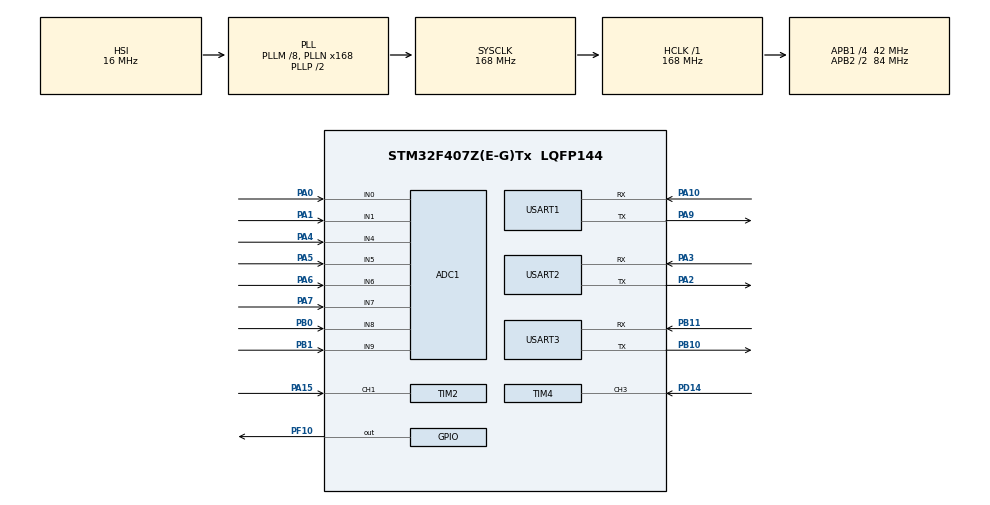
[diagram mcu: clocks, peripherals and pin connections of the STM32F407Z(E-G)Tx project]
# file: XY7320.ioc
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ADC1.Channel-0\#ChannelRegularConversion=ADC_CHANNEL_0
ADC1.Channel-1\#ChannelRegularConversion=ADC_CHANNEL_1
ADC1.Channel-2\#ChannelRegularConversion=ADC_CHANNEL_4
ADC1.Channel-3\#ChannelRegularConversion=ADC_CHANNEL_5
ADC1.Channel-4\#ChannelRegularConversion=ADC_CHANNEL_6
ADC1.Channel-5\#ChannelRegularConversion=ADC_CHANNEL_7
ADC1.Channel-6\#ChannelRegularConversion=ADC_CHANNEL_8
ADC1.Channel-7\#ChannelRegularConversion=ADC_CHANNEL_9
ADC1.DMAContinuousRequests=ENABLE
ADC1.ExternalTrigConv=ADC_EXTERNALTRIGCONV_T3_TRGO
ADC1.NbrOfConversion=8
ADC1.NbrOfConversionFlag=1
ADC1.Rank-0\#ChannelRegularConversion=1
ADC1.Rank-1\#ChannelRegularConversion=2
ADC1.Rank-2\#ChannelRegularConversion=3
ADC1.Rank-3\#ChannelRegularConversion=4
ADC1.Rank-4\#ChannelRegularConversion=5
ADC1.Rank-5\#ChannelRegularConversion=6
ADC1.Rank-6\#ChannelRegularConversion=7
ADC1.Rank-7\#ChannelRegularConversion=8
ADC1.SamplingTime-0\#ChannelRegularConversion=ADC_SAMPLETIME_15CYCLES
ADC1.SamplingTime-1\#ChannelRegularConversion=ADC_SAMPLETIME_15CYCLES
ADC1.SamplingTime-2\#ChannelRegularConversion=ADC_SAMPLETIME_15CYCLES
ADC1.SamplingTime-3\#ChannelRegularConversion=ADC_SAMPLETIME_15CYCLES
ADC1.SamplingTime-4\#ChannelRegularConversion=ADC_SAMPLETIME_15CYCLES
ADC1.SamplingTime-5\#ChannelRegularConversion=ADC_SAMPLETIME_15CYCLES
ADC1.SamplingTime-6\#ChannelRegularConversion=ADC_SAMPLETIME_15CYCLES
ADC1.SamplingTime-7\#ChannelRegularConversion=ADC_SAMPLETIME_15CYCLES
ADC1.ScanConvMode=ENABLE
ADC1.master=1
Dma.ADC1.1.Direction=DMA_PERIPH_TO_MEMORY
Dma.ADC1.1.FIFOMode=DMA_FIFOMODE_DISABLE
Dma.ADC1.1.Instance=DMA2_Stream0
Dma.ADC1.1.MemDataAlignment=DMA_MDATAALIGN_HALFWORD
Dma.ADC1.1.MemInc=DMA_MINC_ENABLE
Dma.ADC1.1.Mode=DMA_CIRCULAR
Dma.ADC1.1.PeriphDataAlignment=DMA_PDATAALIGN_HALFWORD
Dma.ADC1.1.PeriphInc=DMA_PINC_DISABLE
Dma.ADC1.1.Priority=DMA_PRIORITY_LOW
Dma.Request0=USART2_RX
Dma.Request1=ADC1
Dma.Request2=USART3_RX
Dma.Request3=USART2_TX
Dma.USART2_RX.0.Direction=DMA_PERIPH_TO_MEMORY
Dma.USART2_RX.0.FIFOMode=DMA_FIFOMODE_DISABLE
Dma.USART2_RX.0.Instance=DMA1_Stream5
Dma.USART2_RX.0.MemDataAlignment=DMA_MDATAALIGN_BYTE
Dma.USART2_RX.0.MemInc=DMA_MINC_ENABLE
Dma.USART2_RX.0.Mode=DMA_NORMAL
Dma.USART2_RX.0.PeriphDataAlignment=DMA_PDATAALIGN_BYTE
Dma.USART2_RX.0.PeriphInc=DMA_PINC_DISABLE
Dma.USART2_RX.0.Priority=DMA_PRIORITY_LOW
Dma.USART2_TX.3.Direction=DMA_MEMORY_TO_PERIPH
Dma.USART2_TX.3.FIFOMode=DMA_FIFOMODE_DISABLE
Dma.USART2_TX.3.Instance=DMA1_Stream6
Dma.USART2_TX.3.MemDataAlignment=DMA_MDATAALIGN_BYTE
Dma.USART2_TX.3.MemInc=DMA_MINC_ENABLE
Dma.USART2_TX.3.Mode=DMA_NORMAL
Dma.USART2_TX.3.PeriphDataAlignment=DMA_PDATAALIGN_BYTE
Dma.USART2_TX.3.PeriphInc=DMA_PINC_DISABLE
Dma.USART2_TX.3.Priority=DMA_PRIORITY_LOW
Dma.USART3_RX.2.Direction=DMA_PERIPH_TO_MEMORY
Dma.USART3_RX.2.FIFOMode=DMA_FIFOMODE_DISABLE
Dma.USART3_RX.2.Instance=DMA1_Stream1
Dma.USART3_RX.2.MemDataAlignment=DMA_MDATAALIGN_BYTE
Dma.USART3_RX.2.MemInc=DMA_MINC_ENABLE
Dma.USART3_RX.2.Mode=DMA_NORMAL
Dma.USART3_RX.2.PeriphDataAlignment=DMA_PDATAALIGN_BYTE
Dma.USART3_RX.2.PeriphInc=DMA_PINC_DISABLE
Dma.USART3_RX.2.Priority=DMA_PRIORITY_LOW
Mcu.Family=STM32F4
Mcu.Name=STM32F407Z(E-G)Tx
Mcu.Package=LQFP144
NVIC.ADC_IRQn=true\:0\:0\:false\:false\:true\:true\:true\:true
NVIC.DMA1_Stream1_IRQn=true\:0\:0\:false\:false\:true\:false\:true\:true
NVIC.DMA1_Stream5_IRQn=true\:0\:0\:false\:false\:true\:false\:true\:true
NVIC.DMA1_Stream6_IRQn=true\:0\:0\:false\:false\:true\:false\:true\:true
NVIC.DMA2_Stream0_IRQn=true\:0\:0\:false\:false\:true\:false\:true\:true
NVIC.PriorityGroup=NVIC_PRIORITYGROUP_4
NVIC.TIM2_IRQn=true\:0\:0\:false\:false\:true\:true\:true\:true
NVIC.TIM4_IRQn=true\:0\:0\:false\:false\:true\:true\:true\:true
NVIC.TIM8_TRG_COM_TIM14_IRQn=true\:0\:0\:false\:false\:true\:true\:true\:true
NVIC.USART2_IRQn=true\:0\:0\:false\:false\:true\:true\:true\:true
NVIC.USART3_IRQn=true\:0\:0\:false\:false\:true\:true\:true\:true
PA0-WKUP.Signal=ADCx_IN0
PA1.Signal=ADCx_IN1
PA10.Mode=Asynchronous
PA10.Signal=USART1_RX
PA13.Mode=Serial_Wire
PA13.Signal=SYS_JTMS-SWDIO
PA14.Mode=Serial_Wire
PA14.Signal=SYS_JTCK-SWCLK
PA15.Signal=S_TIM2_CH1_ETR
PA2.Mode=Asynchronous
PA2.Signal=USART2_TX
PA3.Mode=Asynchronous
PA3.Signal=USART2_RX
PA4.Signal=ADCx_IN4
PA5.Signal=ADCx_IN5
PA6.Signal=ADCx_IN6
PA7.Signal=ADCx_IN7
PA9.Mode=Asynchronous
PA9.Signal=USART1_TX
PB0.Signal=ADCx_IN8
PB1.Signal=ADCx_IN9
PB10.Mode=Asynchronous
PB10.Signal=USART3_TX
PB11.Mode=Asynchronous
PB11.Signal=USART3_RX
PC14-OSC32_IN.Mode=LSE-External-Oscillator
PC14-OSC32_IN.Signal=RCC_OSC32_IN
PC15-OSC32_OUT.Mode=LSE-External-Oscillator
PC15-OSC32_OUT.Signal=RCC_OSC32_OUT
PD14.Signal=S_TIM4_CH3
PF10.Signal=GPIO_Output
PH0-OSC_IN.Mode=HSE-External-Oscillator
PH0-OSC_IN.Signal=RCC_OSC_IN
PH1-OSC_OUT.Mode=HSE-External-Oscillator
PH1-OSC_OUT.Signal=RCC_OSC_OUT
ProjectManager.HeapSize=0x200
ProjectManager.StackSize=0x400
ProjectManager.TargetToolchain=STM32CubeIDE
RCC.48MHZClocksFreq_Value=84000000
RCC.AHBFreq_Value=168000000
RCC.APB1CLKDivider=RCC_HCLK_DIV4
RCC.APB1Freq_Value=42000000
RCC.APB1TimFreq_Value=84000000
RCC.APB2CLKDivider=RCC_HCLK_DIV2
RCC.APB2Freq_Value=84000000
RCC.APB2TimFreq_Value=168000000
RCC.CortexFreq_Value=168000000
RCC.HCLKFreq_Value=168000000
RCC.HSE_VALUE=8000000
RCC.HSI_VALUE=16000000
RCC.PLLM=8
RCC.PLLN=168
RCC.SYSCLKFreq_VALUE=168000000
RCC.SYSCLKSource=RCC_SYSCLKSOURCE_PLLCLK
RCC.VCOOutputFreq_Value=336000000
SH.ADCx_IN0.0=ADC1_IN0,IN0
SH.ADCx_IN1.0=ADC1_IN1,IN1
SH.ADCx_IN4.0=ADC1_IN4,IN4
SH.ADCx_IN5.0=ADC1_IN5,IN5
SH.ADCx_IN6.0=ADC1_IN6,IN6
SH.ADCx_IN7.0=ADC1_IN7,IN7
SH.ADCx_IN8.0=ADC1_IN8,IN8
SH.ADCx_IN9.0=ADC1_IN9,IN9
SH.S_TIM2_CH1_ETR.0=TIM2_CH1,Input_Capture1_from_TI1
SH.S_TIM4_CH3.0=TIM4_CH3,Input_Capture3_from_TI3
TIM14.AutoReloadPreload=TIM_AUTORELOAD_PRELOAD_ENABLE
TIM14.Period=1000-1
TIM14.Prescaler=84-1
TIM2.AutoReloadPreload=TIM_AUTORELOAD_PRELOAD_ENABLE
TIM2.Channel-Input_Capture1_from_TI1=TIM_CHANNEL_1
TIM2.ClockDivision=TIM_CLOCKDIVISION_DIV2
TIM2.ICPolarity_CH1=TIM_INPUTCHANNELPOLARITY_BOTHEDGE
TIM2.Prescaler=83
TIM3.AutoReloadPreload=TIM_AUTORELOAD_PRELOAD_ENABLE
TIM3.Period=840-1
TIM3.TIM_MasterOutputTrigger=TIM_TRGO_UPDATE
TIM4.Channel-Input_Capture3_from_TI3=TIM_CHANNEL_3
USART1.VirtualMode=VM_ASYNC
USART2.VirtualMode=VM_ASYNC
USART3.VirtualMode=VM_ASYNC
VP_TIM14_VS_ClockSourceINT.Mode=Enable_Timer
VP_TIM3_VS_ClockSourceINT.Mode=Internal
board=custom

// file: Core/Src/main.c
/* USER CODE BEGIN Header */
/**
  ******************************************************************************
  * @file           : main.c
  * @brief          : Main program body
  ******************************************************************************
  * @attention
  *
  * Copyright (c) 2026 STMicroelectronics.
  * All rights reserved.
  *
  * This software is licensed under terms that can be found in the LICENSE file
  * in the root directory of this software component.
  * If no LICENSE file comes with this software, it is provided AS-IS.
  *
  ******************************************************************************
  */
/* USER CODE END Header */
#include "main.h"
#include "adc.h"
#include "dma.h"
#include "tim.h"
#include "usart.h"
#include "gpio.h"

/* USER CODE BEGIN Includes */
#include "app_main.h"
#include "bsp_tim_os.h"
#include "os.h"
/* USER CODE END Includes */

void SystemClock_Config(void);

int main(void)
{

  /* USER CODE BEGIN 1 */
  SCB->VTOR = 0x08010000U;
  __enable_irq();

  /* 直接寄存器操作... */
  RCC->AHB1ENR |= RCC_AHB1ENR_GPIOFEN;
  /* USER CODE END 1 */

  /* MCU Configuration--------------------------------------------------------*/

  /* Reset of all peripherals, Initializes the Flash interface and the Systick. */
  HAL_Init();

  /* Configure the system clock */
  SystemClock_Config();

  /* Initialize all configured peripherals */
  MX_GPIO_Init();
  MX_DMA_Init();
  MX_USART1_UART_Init();
  MX_USART2_UART_Init();
  MX_TIM14_Init();
  MX_ADC1_Init();
  MX_TIM3_Init();
  MX_USART3_UART_Init();
  MX_TIM2_Init();
  MX_TIM4_Init();
  /* USER CODE BEGIN 2 */
  OS_Init();
  BspTimOs_SetTickCallback(OS_Tick);
  BspTimOs_Init(&htim14);

  App_Main_Init();    // 初始化 App 层
  App_Main_Start();   // 创建所有任务
  OS_Start();        // 启动调度器（不会返回）
  /* USER CODE END 2 */

  /* Infinite loop */
  while (1)
  {

  }
}

void SystemClock_Config(void)
{
  RCC_OscInitTypeDef RCC_OscInitStruct = {0};
  RCC_ClkInitTypeDef RCC_ClkInitStruct = {0};

  /** Configure the main internal regulator output voltage
  */
  __HAL_RCC_PWR_CLK_ENABLE();
  __HAL_PWR_VOLTAGESCALING_CONFIG(PWR_REGULATOR_VOLTAGE_SCALE1);

  /** Initializes the RCC Oscillators according to the specified parameters
  * in the RCC_OscInitTypeDef structure.
  */
  RCC_OscInitStruct.OscillatorType = RCC_OSCILLATORTYPE_HSI;
  RCC_OscInitStruct.HSIState = RCC_HSI_ON;
  RCC_OscInitStruct.HSICalibrationValue = RCC_HSICALIBRATION_DEFAULT;
  RCC_OscInitStruct.PLL.PLLState = RCC_PLL_ON;
  RCC_OscInitStruct.PLL.PLLSource = RCC_PLLSOURCE_HSI;
  RCC_OscInitStruct.PLL.PLLM = 8;
  RCC_OscInitStruct.PLL.PLLN = 168;
  RCC_OscInitStruct.PLL.PLLP = RCC_PLLP_DIV2;
  RCC_OscInitStruct.PLL.PLLQ = 4;
  if (HAL_RCC_OscConfig(&RCC_OscInitStruct) != HAL_OK)
  {
    Error_Handler();
  }

  /** Initializes the CPU, AHB and APB buses clocks
  */
  RCC_ClkInitStruct.ClockType = RCC_CLOCKTYPE_HCLK|RCC_CLOCKTYPE_SYSCLK
                              |RCC_CLOCKTYPE_PCLK1|RCC_CLOCKTYPE_PCLK2;
  RCC_ClkInitStruct.SYSCLKSource = RCC_SYSCLKSOURCE_PLLCLK;
  RCC_ClkInitStruct.AHBCLKDivider = RCC_SYSCLK_DIV1;
  RCC_ClkInitStruct.APB1CLKDivider = RCC_HCLK_DIV4;
  RCC_ClkInitStruct.APB2CLKDivider = RCC_HCLK_DIV2;

  if (HAL_RCC_ClockConfig(&RCC_ClkInitStruct, FLASH_LATENCY_5) != HAL_OK)
  {
    Error_Handler();
  }
}

void Error_Handler(void)
{
  __disable_irq();
  while (1)
  {
  }
}
